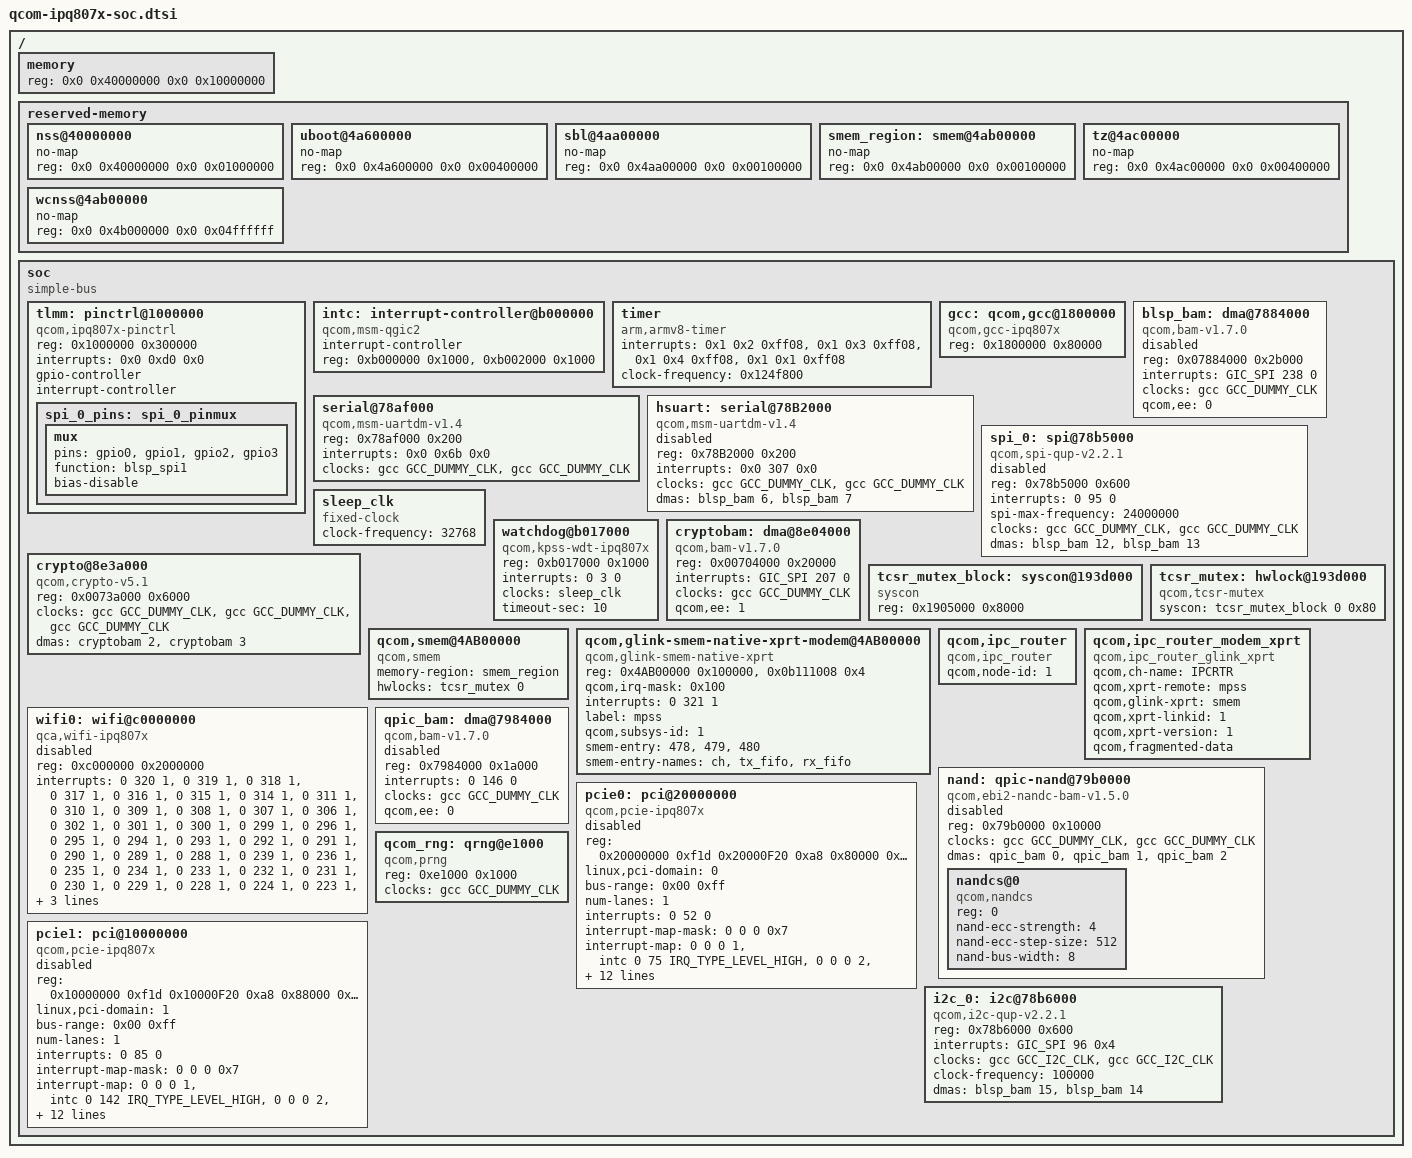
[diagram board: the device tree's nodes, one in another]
/*
 * Copyright (c) 2016, The Linux Foundation. All rights reserved.
 *
 * Permission to use, copy, modify, and/or distribute this software for any
 * purpose with or without fee is hereby granted, provided that the above
 * copyright notice and this permission notice appear in all copies.
 *
 * THE SOFTWARE IS PROVIDED "AS IS" AND THE AUTHOR DISCLAIMS ALL WARRANTIES
 * WITH REGARD TO THIS SOFTWARE INCLUDING ALL IMPLIED WARRANTIES OF
 * MERCHANTABILITY AND FITNESS. IN NO EVENT SHALL THE AUTHOR BE LIABLE FOR
 * ANY SPECIAL, DIRECT, INDIRECT, OR CONSEQUENTIAL DAMAGES OR ANY DAMAGES
 * WHATSOEVER RESULTING FROM LOSS OF USE, DATA OR PROFITS, WHETHER IN AN
 * ACTION OF CONTRACT, NEGLIGENCE OR OTHER TORTIOUS ACTION, ARISING OUT OF
 * OR IN CONNECTION WITH THE USE OR PERFORMANCE OF THIS SOFTWARE.
 */
#include <dt-bindings/reset/qcom,gcc-ipq807x.h>
#include <dt-bindings/interrupt-controller/arm-gic.h>

/ {
	memory {
		device_type = "memory";
		reg = <0x0 0x40000000 0x0 0x10000000>;
	};

	/*
	 * +=========+==============+========================+
	 * |        |              |                         |
	 * | Region | Start Offset |          Size           |
	 * |        |              |                         |
	 * +--------+--------------+-------------------------+
	 * |        |              |                         |
	 * |        |              |                         |
	 * |  NSS   |  0x40000000  |          16MB           |
	 * |        |              |                         |
	 * |        |              |                         |
	 * +--------+--------------+-------------------------+
	 * |        |              |                         |
	 * |        |              |                         |
	 * |        |              |                         |
	 * |        |              |                         |
	 * | Linux  |  0x41000000  | Depends on total memory |
	 * |        |              |                         |
	 * |        |              |                         |
	 * |        |              |                         |
	 * |        |              |                         |
	 * +--------+--------------+-------------------------+
	 * | uboot  |  0x4A600000  |           4MB           |
	 * +--------+--------------+-------------------------+
	 * |  SBL   |  0x4AA00000  |           1MB           |
	 * +--------+--------------+-------------------------+
	 * |  smem  |  0x4AB00000  |           1MB           |
	 * +--------+--------------+-------------------------+
	 * |        |              |                         |
	 * |TZ+APPS |  0x4AC00000  |           4MB           |
	 * |        |              |                         |
	 * +--------+--------------+-------------------------+
	 * |        |              |                         |
	 * |        |              |                         |
	 * |        |              |                         |
	 * |   Q6   |  0x4B000000  |          80MB           |
	 * |        |              |                         |
	 * |        |              |                         |
	 * |        |              |                         |
	 * +--------+--------------+-------------------------+
	 * |                                                 |
	 * |      Linux Memory for variants above 256MB      |
	 * |                                                 |
	 * +=================================================+
	 */

	reserved-memory {
		#address-cells = <2>;
		#size-cells = <2>;
		ranges;

		nss@40000000 {
			no-map;
			reg = <0x0 0x40000000 0x0 0x01000000>;
		};

		uboot@4a600000 {
			no-map;
			reg = <0x0 0x4a600000 0x0 0x00400000>;
		};

		sbl@4aa00000 {
			no-map;
			reg = <0x0 0x4aa00000 0x0 0x00100000>;
		};

		smem_region:smem@4ab00000 {
			no-map;
			reg = <0x0 0x4ab00000 0x0 0x00100000>;
		};

		tz@4ac00000 {	/* TZ and TZ_APPS */
			no-map;
			reg = <0x0 0x4ac00000 0x0 0x00400000>;
		};

		wcnss@4ab00000 {
			no-map;
			reg = <0x0 0x4b000000 0x0 0x04ffffff>;
		};
	};

	soc: soc {
		#address-cells = <0x1>;
		#size-cells = <0x1>;
		ranges = <0x0 0x0 0x0 0xffffffff>;
		compatible = "simple-bus";

		tlmm: pinctrl@1000000 {
			compatible = "qcom,ipq807x-pinctrl";
			reg = <0x1000000 0x300000>;
			interrupts = <0x0 0xd0 0x0>;
			gpio-controller;
			#gpio-cells = <0x2>;
			interrupt-controller;
			#interrupt-cells = <0x2>;

			spi_0_pins: spi_0_pinmux {
				mux {
					pins = "gpio0", "gpio1", "gpio2", "gpio3";
					function = "blsp_spi1";
					bias-disable;
				};
			};
		};

		intc: interrupt-controller@b000000 {
			compatible = "qcom,msm-qgic2";
			interrupt-controller;
			#interrupt-cells = <0x3>;
			reg = <0xb000000 0x1000>,
			<0xb002000 0x1000>;
		};

		timer {
			compatible = "arm,armv8-timer";
			interrupts = <0x1 0x2 0xff08>,
				     <0x1 0x3 0xff08>,
				     <0x1 0x4 0xff08>,
				     <0x1 0x1 0xff08>;
			clock-frequency = <0x124f800>;
		};

		gcc: qcom,gcc@1800000 {
			compatible = "qcom,gcc-ipq807x";
			reg = <0x1800000 0x80000>;
			#clock-cells = <0x1>;
			#reset-cells = <1>;
		};

		blsp_bam: dma@7884000 {
			compatible = "qcom,bam-v1.7.0";
			reg = <0x07884000 0x2b000>;
			interrupts = <GIC_SPI 238 0>;
			clocks = <&gcc GCC_DUMMY_CLK>;
			clock-names = "bam_clk";
			#dma-cells = <1>;
			qcom,ee = <0>;
			status = "disabled";
		};

		serial@78af000 {
			compatible = "qcom,msm-uartdm-v1.4", "qcom,msm-uartdm";
			reg = <0x78af000 0x200>;
			interrupts = <0x0 0x6b 0x0>;
			status = "ok";
			clocks = <&gcc GCC_DUMMY_CLK>,
				 <&gcc GCC_DUMMY_CLK>;
			clock-names = "core", "iface";
		};

		hsuart: serial@78B2000 {
			compatible = "qcom,msm-uartdm-v1.4", "qcom,msm-uartdm";
			reg = <0x78B2000 0x200>;
			interrupts = <0x0 307 0x0>;
			clocks = <&gcc GCC_DUMMY_CLK>,
				 <&gcc GCC_DUMMY_CLK>;
			clock-names = "core", "iface";
			dmas = <&blsp_bam 6>,
				 <&blsp_bam 7>;
			dma-names = "tx", "rx";
			status = "disabled";
		};

		spi_0: spi@78b5000 { /* BLSP1 QUP1 */
			compatible = "qcom,spi-qup-v2.2.1";
			#address-cells = <1>;
			#size-cells = <0>;
			reg = <0x78b5000 0x600>;
			interrupts = <0 95 0>;
			spi-max-frequency = <24000000>;
			clocks = <&gcc GCC_DUMMY_CLK>,
				<&gcc GCC_DUMMY_CLK>;
			clock-names = "core", "iface";
			dmas = <&blsp_bam 12>, <&blsp_bam 13>;
			dma-names = "tx", "rx";
			status = "disabled";
		};

		sleep_clk: sleep_clk {
			compatible = "fixed-clock";
			clock-frequency = <32768>;
			#clock-cells = <0>;
		};

		watchdog@b017000 {
			compatible = "qcom,kpss-wdt-ipq807x";
			reg = <0xb017000 0x1000>;
			interrupt-names = "bark_irq";
			interrupts = <0 3 0>;
			clocks = <&sleep_clk>;
			timeout-sec = <10>;
		};

		cryptobam: dma@8e04000 {
			compatible = "qcom,bam-v1.7.0";
			reg = <0x00704000 0x20000>;
			interrupts = <GIC_SPI 207 0>;
			clocks = <&gcc GCC_DUMMY_CLK>;
			clock-names = "bam_clk";
			#dma-cells = <1>;
			qcom,ee = <1>;
		};

		crypto@8e3a000 {
			compatible = "qcom,crypto-v5.1";
			reg = <0x0073a000 0x6000>;
			clocks = <&gcc GCC_DUMMY_CLK>,
				<&gcc GCC_DUMMY_CLK>,
				<&gcc GCC_DUMMY_CLK>;
			clock-names = "iface", "bus", "core";
			dmas = <&cryptobam 2>, <&cryptobam 3>;
			dma-names = "rx", "tx";
		};

		tcsr_mutex_block: syscon@193d000 {
			compatible = "syscon";
			reg = <0x1905000 0x8000>;
		};

		tcsr_mutex: hwlock@193d000 {
			compatible = "qcom,tcsr-mutex";
			syscon = <&tcsr_mutex_block 0 0x80>;
			#hwlock-cells = <1>;
		};

		qcom,smem@4AB00000 {
			compatible = "qcom,smem";
			memory-region = <&smem_region>;
			hwlocks = <&tcsr_mutex 0>;
		};

		qcom,glink-smem-native-xprt-modem@4AB00000 {
			compatible = "qcom,glink-smem-native-xprt";
			reg = <0x4AB00000 0x100000>, <0x0b111008 0x4>;
			reg-names = "smem", "irq-reg-base";
			qcom,irq-mask = <0x100>;
			interrupts = <0 321 1>;
			label = "mpss";
			qcom,subsys-id = <1>;
			smem-entry = <478>, <479>, <480>;
			smem-entry-names = "ch", "tx_fifo", "rx_fifo";
		};

		qcom,ipc_router {
			compatible = "qcom,ipc_router";
			qcom,node-id = <1>;
		};

		qcom,ipc_router_modem_xprt {
			compatible = "qcom,ipc_router_glink_xprt";
			qcom,ch-name = "IPCRTR";
			qcom,xprt-remote = "mpss";
			qcom,glink-xprt = "smem";
			qcom,xprt-linkid = <1>;
			qcom,xprt-version = <1>;
			qcom,fragmented-data;
		};

		wifi0: wifi@c0000000 {
			compatible = "qca,wifi-ipq807x";
			reg = <0xc000000 0x2000000>;
			interrupts = <0 320 1>, /* o_wcss_apps_intr[0] =  */
				<0 319 1>,
				<0 318 1>,
				<0 317 1>,
				<0 316 1>,
				<0 315 1>,
				<0 314 1>,
				<0 311 1>,
				<0 310 1>,
				<0 309 1>,
				<0 308 1>,
				<0 307 1>,
				<0 306 1>,
				<0 302 1>,
				<0 301 1>,
				<0 300 1>,
				<0 299 1>,
				<0 296 1>,
				<0 295 1>,
				<0 294 1>,
				<0 293 1>,
				<0 292 1>,
				<0 291 1>,
				<0 290 1>,
				<0 289 1>,
				<0 288 1>, /* o_wcss_apps_intr[25] */
				<0 239 1>,
				<0 236 1>,
				<0 235 1>,
				<0 234 1>,
				<0 233 1>,
				<0 232 1>,
				<0 231 1>,
				<0 230 1>,
				<0 229 1>,
				<0 228 1>,
				<0 224 1>,
				<0 223 1>,
				<0 203 1>,
				<0 183 1>,
				<0 180 1>,
				<0 179 1>,
				<0 178 1>,
				<0 177 1>,
				<0 176 1>,
				<0 163 1>,
				<0 162 1>,
				<0 160 1>,
				<0 159 1>,
				<0 158 1>,
				<0 157 1>,
				<0 156 1>; /* o_wcss_apps_intr[51] */

			interrupt-names = "misc-pulse1",
				"misc-latch",
				"sw-exception",
				"watchdog",
				"ce0",
				"ce1",
				"ce2",
				"ce3",
				"ce4",
				"ce5",
				"ce6",
				"ce7",
				"ce8",
				"ce9",
				"ce10",
				"ce11",
				"host2wbm-desc-feed",
				"host2reo-re-injection",
				"host2reo-command",
				"host2rxdma-monitor-ring3",
				"host2rxdma-monitor-ring2",
				"host2rxdma-monitor-ring1",
				"reo2ost-exception",
				"wbm2host-rx-release",
				"reo2host-status",
				"reo2host-destination-ring4",
				"reo2host-destination-ring3",
				"reo2host-destination-ring2",
				"reo2host-destination-ring1",
				"rxdma2host-monitor-destination-mac3",
				"rxdma2host-monitor-destination-mac2",
				"rxdma2host-monitor-destination-mac1",
				"ppdu-end-interrupts-mac3",
				"ppdu-end-interrupts-mac2",
				"ppdu-end-interrupts-mac1",
				"rxdma2host-monitor-status-ring-mac3",
				"rxdma2host-monitor-status-ring-mac2",
				"rxdma2host-monitor-status-ring-mac1",
				"host2rxdma-host-buf-ring-mac3",
				"host2rxdma-host-buf-ring-mac2",
				"host2rxdma-host-buf-ring-mac1",
				"rxdma2host-destination-ring-mac3",
				"rxdma2host-destination-ring-mac2",
				"rxdma2host-destination-ring-mac1",
				"host2tcl-input-ring4",
				"host2tcl-input-ring3",
				"host2tcl-input-ring2",
				"host2tcl-input-ring1",
				"wbm2host-tx-completions-ring3",
				"wbm2host-tx-completions-ring2",
				"wbm2host-tx-completions-ring1",
				"tcl2host-status-ring";
			status = "disabled";
		};

		qpic_bam: dma@7984000 {
			compatible = "qcom,bam-v1.7.0";
			reg = <0x7984000 0x1a000>;
			interrupts = <0 146 0>;
			clocks = <&gcc GCC_DUMMY_CLK>;
			clock-names = "bam_clk";
			#dma-cells = <1>;
			qcom,ee = <0>;
			status = "disabled";
		};

		nand: qpic-nand@79b0000 {
			compatible = "qcom,ebi2-nandc-bam-v1.5.0";
			reg = <0x79b0000 0x10000>;
			#address-cells = <1>;
			#size-cells = <0>;
			clocks = <&gcc GCC_DUMMY_CLK>,
				<&gcc GCC_DUMMY_CLK>;
			clock-names = "core", "aon";

			dmas = <&qpic_bam 0>,
				<&qpic_bam 1>,
				<&qpic_bam 2>;
			dma-names = "tx", "rx", "cmd";
			status = "disabled";

			nandcs@0 {
				compatible = "qcom,nandcs";
				reg = <0>;
				#address-cells = <1>;
				#size-cells = <1>;

				nand-ecc-strength = <4>;
				nand-ecc-step-size = <512>;
				nand-bus-width = <8>;
			};
		};


		pcie0: pci@20000000 {
			compatible = "qcom,pcie-ipq807x";
			reg =  <0x20000000 0xf1d
				0x20000F20 0xa8
				0x80000 0x2000
				0x20100000 0x1000>;
			reg-names = "dbi", "elbi", "parf", "config";
			device_type = "pci";
			linux,pci-domain = <0>;
			bus-range = <0x00 0xff>;
			num-lanes = <1>;
			#address-cells = <3>;
			#size-cells = <2>;

			ranges = <0x81000000 0 0x20200000 0x20200000
				  0 0x00100000   /* downstream I/O */
				  0x82000000 0 0x20300000 0x20300000
				  0 0x00d00000>; /* non-prefetchable memory */

			interrupts = <0 52 0>;
			interrupt-names = "msi";
			#interrupt-cells = <1>;
			interrupt-map-mask = <0 0 0 0x7>;
			interrupt-map = <0 0 0 1 &intc 0 75
					 IRQ_TYPE_LEVEL_HIGH>, /* int_a */
					<0 0 0 2 &intc 0 78
					 IRQ_TYPE_LEVEL_HIGH>, /* int_b */
					<0 0 0 3 &intc 0 79
					 IRQ_TYPE_LEVEL_HIGH>, /* int_c */
					<0 0 0 4 &intc 0 83
					 IRQ_TYPE_LEVEL_HIGH>; /* int_d */
			clocks = <&gcc GCC_DUMMY_CLK>,
				 <&gcc GCC_DUMMY_CLK>,
				 <&gcc GCC_DUMMY_CLK>,
				 <&gcc GCC_DUMMY_CLK>,
				 <&gcc GCC_DUMMY_CLK>,
				 <&gcc GCC_DUMMY_CLK>,
				 <&gcc GCC_DUMMY_CLK>;
			clock-names = "boot",
				      "axi_m",
				      "axi_s",
				      "ahb",
				      "aux",
				      "pipe",
				      "phy";

			resets = <&gcc GCC_PCIE0_BCR>,
				 <&gcc GCC_PCIE0_PHY_BCR>,
				 <&gcc GCC_PCIE0PHY_PHY_BCR>;
			reset-names = "pci",
				      "phy",
				      "phy1";

			perst-gpio = <&tlmm 58 1>;
			is_emulation = <1>;
			status = "disabled";
		};

		pcie1: pci@10000000 {
			compatible = "qcom,pcie-ipq807x";
			reg =  <0x10000000 0xf1d
				0x10000F20 0xa8
				0x88000 0x2000
				0x10100000 0x1000>;
			reg-names = "dbi", "elbi", "parf", "config";
			device_type = "pci";
			linux,pci-domain = <1>;
			bus-range = <0x00 0xff>;
			num-lanes = <1>;
			#address-cells = <3>;
			#size-cells = <2>;

			ranges = <0x81000000 0 0x10200000 0x10200000
				  0 0x00100000   /* downstream I/O */
				  0x82000000 0 0x10300000 0x10300000
				  0 0x00d00000>; /* non-prefetchable memory */

			interrupts = <0 85 0>;
			interrupt-names = "msi";
			#interrupt-cells = <1>;
			interrupt-map-mask = <0 0 0 0x7>;
			interrupt-map = <0 0 0 1 &intc 0 142
					 IRQ_TYPE_LEVEL_HIGH>, /* int_a */
					<0 0 0 2 &intc 0 143
					 IRQ_TYPE_LEVEL_HIGH>, /* int_b */
					<0 0 0 3 &intc 0 144
					 IRQ_TYPE_LEVEL_HIGH>, /* int_c */
					<0 0 0 4 &intc 0 145
					 IRQ_TYPE_LEVEL_HIGH>; /* int_d */
			clocks = <&gcc GCC_DUMMY_CLK>,
				 <&gcc GCC_DUMMY_CLK>,
				 <&gcc GCC_DUMMY_CLK>,
				 <&gcc GCC_DUMMY_CLK>,
				 <&gcc GCC_DUMMY_CLK>,
				 <&gcc GCC_DUMMY_CLK>,
				 <&gcc GCC_DUMMY_CLK>;
			clock-names = "boot",
				      "axi_m",
				      "axi_s",
				      "ahb",
				      "aux",
				      "pipe",
				      "phy";

			resets = <&gcc GCC_PCIE0_BCR>,
				 <&gcc GCC_PCIE0_PHY_BCR>,
				 <&gcc GCC_PCIE0PHY_PHY_BCR>;
			reset-names = "pci",
				      "phy",
				      "phy1";

			perst-gpio = <&tlmm 61 1>;
			is_emulation = <1>;
			status = "disabled";
		};

		i2c_0: i2c@78b6000 {
			compatible = "qcom,i2c-qup-v2.2.1";
			#address-cells = <1>;
			#size-cells = <0>;
			reg = <0x78b6000 0x600>;
			interrupts = <GIC_SPI 96 0x4>;
			clocks = <&gcc GCC_I2C_CLK>,
				<&gcc GCC_I2C_CLK>;
			clock-names = "iface", "core";
			clock-frequency  = <100000>;
			dmas = <&blsp_bam 15>, <&blsp_bam 14>;
			dma-names = "rx", "tx";
		};

		qcom_rng: qrng@e1000 {
			compatible = "qcom,prng";
			reg = <0xe1000 0x1000>;
			clocks = <&gcc GCC_DUMMY_CLK>;
			clock-names = "core";
		};
	};
};
